# APM32F411 register map
File version: 1.0
CPU: CM4 r1p0, little endian, no MPU, no FPU, 3 interrupt priority bits
Registers are 32-bit, read-write, reset 0x0 unless marked. A register's access mark holds for its fields unless they carry their own. Offsets are from the block's base; [hi:lo] are bit positions.

## IWDT — Independent watchdog
Base 0x40003000
0x00 KEY wo
  [15:0] KEY — Key value (write only, read 0000h)
0x04 PSC — Prescaler register
  [2:0] PSC — Prescaler divider
0x08 CNTRLD reset 0xFFF — Reload register
  [11:0] CNTRLD — Watchdog counter reload value
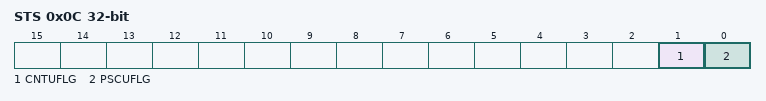
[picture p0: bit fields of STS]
0x0C STS ro — Status register
  [1] CNTUFLG — Watchdog counter reload value update
  [0] PSCUFLG — Watchdog prescaler value update

## WWDT — Window watchdog
Base 0x40002C00
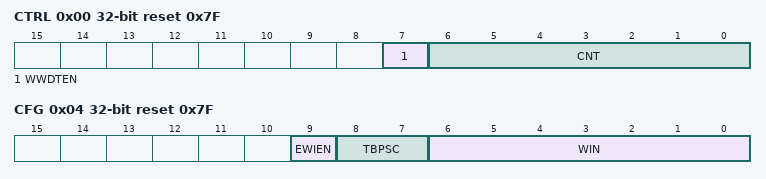
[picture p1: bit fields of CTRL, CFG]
0x00 CTRL reset 0x7F — Control register
  [7] WWDTEN — Activation bit
  [6:0] CNT — 7-bit counter (MSB to LSB)
0x04 CFG reset 0x7F — Configuration register
  [9] EWIEN — Early wakeup interrupt
  [8:7] TBPSC — Timer Base Prescaler Factor Configure
  [6:0] WIN — 7-bit window value
0x08 STS — Status register
  [0] EWIFLG — Early wakeup interrupt flag

## UART4 — Universal synchronous asynchronous receiver transmitter
Base 0x40004C00
Same registers: UART5 0x40005000
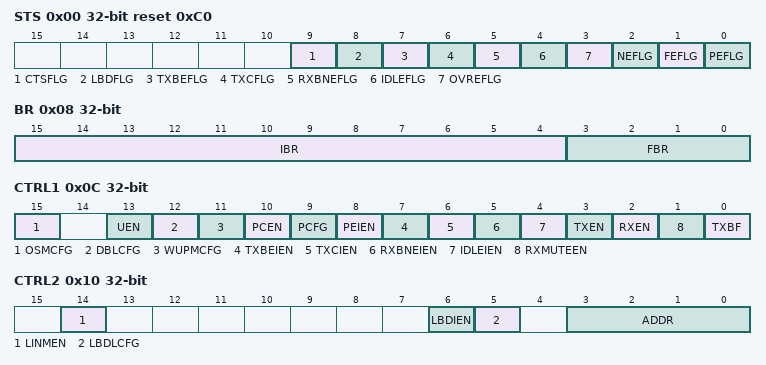
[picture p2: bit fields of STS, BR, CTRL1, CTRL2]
0x00 STS access per field reset 0xC0 — Status register
  [9] CTSFLG rw — CTS Change Flag
  [8] LBDFLG rw — LIN break detection flag
  [7] TXBEFLG ro — Transmit data register empty
  [6] TXCFLG rw — Transmission complete
  [5] RXBNEFLG rw — Read data register not empty
  [4] IDLEFLG ro — IDLE line detected
  [3] OVREFLG ro — Overrun error
  [2] NEFLG ro — Noise detected flag
  [1] FEFLG ro — Framing error
  [0] PEFLG ro — Parity error
0x04 DATA
  [8:0] DATA — Data value
0x08 BR — Baud rate register
  [15:4] IBR — mantissa of USARTDIV
  [3:0] FBR — fraction of USARTDIV
0x0C CTRL1 — Control register 1
  [15] OSMCFG — Oversampling mode
  [13] UEN — USART enable
  [12] DBLCFG — Word length
  [11] WUPMCFG — Wakeup method
  [10] PCEN — Parity control enable
  [9] PCFG — Parity selection
  [8] PEIEN — PE interrupt enable
  [7] TXBEIEN — TXE interrupt enable
  [6] TXCIEN — Transmission complete interrupt enable
  [5] RXBNEIEN — RXNE interrupt enable
  [4] IDLEIEN — IDLE interrupt enable
  [3] TXEN — Transmitter enable
  [2] RXEN — Receiver enable
  [1] RXMUTEEN — Receiver wakeup
  [0] TXBF — Send break
0x10 CTRL2 — Control register 2
  [14] LINMEN — LIN mode enable
  [6] LBDIEN — LIN break detection interrupt enable
  [5] LBDLCFG — lin break detection length
  [3:0] ADDR — Address of the USART node
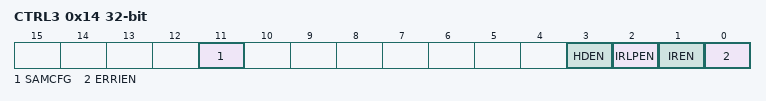
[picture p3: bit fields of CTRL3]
0x14 CTRL3 — Control register 3
  [11] SAMCFG — One sample bit method enable
  [3] HDEN — Half-duplex selection
  [2] IRLPEN — IrDA low-power
  [1] IREN — IrDA mode enable
  [0] ERRIEN — Error interrupt enable

## TMR9 — General purpose timers
Base 0x40014000
Same registers: TMR12 0x40001800
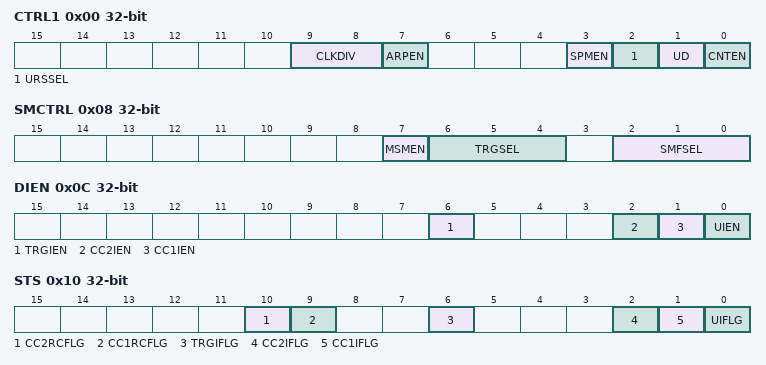
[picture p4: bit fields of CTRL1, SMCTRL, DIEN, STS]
0x00 CTRL1 — control register 1
  [9:8] CLKDIV — Clock division
  [7] ARPEN — Auto-reload preload enable
  [3] SPMEN — One-pulse mode
  [2] URSSEL — Update request source
  [1] UD — Update disable
  [0] CNTEN — Counter enable
0x08 SMCTRL — slave mode control register
  [7] MSMEN — Master/Slave mode
  [6:4] TRGSEL — Trigger selection
  [2:0] SMFSEL — Slave mode selection
0x0C DIEN — DMA/Interrupt enable register
  [6] TRGIEN — Trigger interrupt enable
  [2] CC2IEN — Capture/Compare 2 interrupt enable
  [1] CC1IEN — Capture/Compare 1 interrupt enable
  [0] UIEN — Update interrupt enable
0x10 STS — status register
  [10] CC2RCFLG — Capture/compare 2 overcapture flag
  [9] CC1RCFLG — Capture/Compare 1 overcapture flag
  [6] TRGIFLG — Trigger interrupt flag
  [2] CC2IFLG — Capture/Compare 2 interrupt flag
  [1] CC1IFLG — Capture/compare 1 interrupt flag
  [0] UIFLG — Update interrupt flag
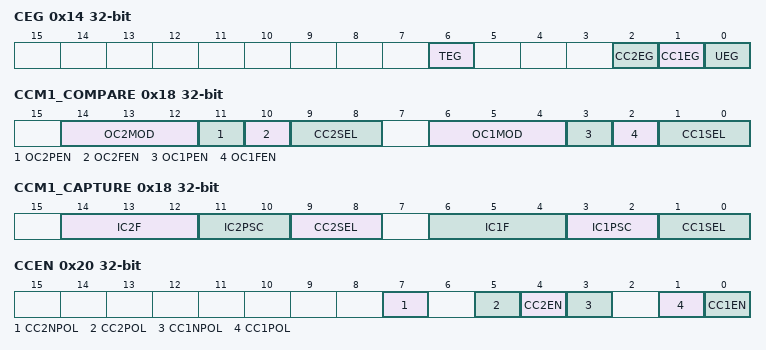
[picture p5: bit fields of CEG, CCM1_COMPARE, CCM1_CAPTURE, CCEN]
0x14 CEG wo — control event generation register
  [6] TEG — Trigger generation
  [2] CC2EG — Capture/compare 2 generation
  [1] CC1EG — Capture/compare 1 generation
  [0] UEG — Update generation
0x18 CCM1_COMPARE — capture/compare mode register 1 (output mode)
  [14:12] OC2MOD — Output Compare 2 mode
  [11] OC2PEN — Output Compare 2 preload enable
  [10] OC2FEN — Output Compare 2 fast enable
  [9:8] CC2SEL — Capture/Compare 2 selection
  [6:4] OC1MOD — Output Compare 1 mode
  [3] OC1PEN — Output Compare 1 preload enable
  [2] OC1FEN — Output Compare 1 fast enable
  [1:0] CC1SEL — Capture/Compare 1 selection
0x18 CCM1_CAPTURE (alternate view of CCM1_COMPARE) — capture/compare mode register 1 (input mode)
  [14:12] IC2F — Input capture 2 filter
  [11:10] IC2PSC — Input capture 2 prescaler
  [9:8] CC2SEL — Capture/Compare 2 selection
  [6:4] IC1F — Input capture 1 filter
  [3:2] IC1PSC — Input capture 1 prescaler
  [1:0] CC1SEL — Capture/Compare 1 selection
0x20 CCEN — capture/compare enable register
  [7] CC2NPOL — Capture/Compare 2 output Polarity
  [5] CC2POL — Capture/Compare 2 output Polarity
  [4] CC2EN — Capture/Compare 2 output enable
  [3] CC1NPOL — Capture/Compare 1 output Polarity
  [1] CC1POL — Capture/Compare 1 output Polarity
  [0] CC1EN — Capture/Compare 1 output enable
0x24 CNT — counter
  [15:0] CNT — counter value
0x28 PSC — prescaler
  [15:0] PSC — Prescaler value
0x2C AUTORLD reset 0xFFFF — auto-reload register
  [15:0] AUTORLD — Auto-reload value
0x34 CC1 — capture/compare register 1
  [15:0] CC1 — Capture/Compare 1 value
0x38 CC2 — capture/compare register 2
  [15:0] CC2 — Capture/Compare 2 value
